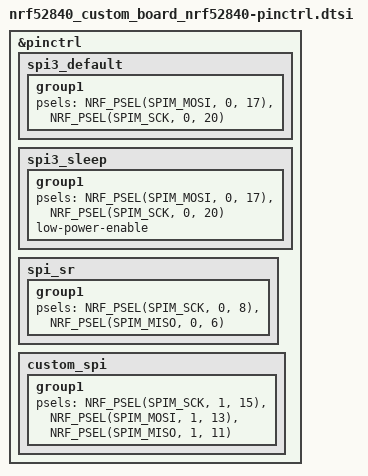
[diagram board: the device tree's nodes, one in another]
/*
 * Copyright (c) 2022 Nordic Semiconductor
 * SPDX-License-Identifier: Apache-2.0
 */

&pinctrl {
	spi3_default: spi3_default {
		group1 {
			psels = <NRF_PSEL(SPIM_MOSI, 0, 17)>,
					<NRF_PSEL(SPIM_SCK, 0, 20)>;
		};
	};

	spi3_sleep: spi3_sleep {
		group1 {
			psels = <NRF_PSEL(SPIM_MOSI, 0, 17)>,
					<NRF_PSEL(SPIM_SCK, 0, 20)>;
			low-power-enable;
		};
	};

	spi_sr: spi_sr{
		group1 {
            psels = <NRF_PSEL(SPIM_SCK, 0, 8)>, // CLK
					<NRF_PSEL(SPIM_MISO, 0, 6)>; // QH (pin 9)
        };
	};

	custom_spi: custom_spi {
                group1 {
                        psels = <NRF_PSEL(SPIM_SCK, 1, 15)>,
                                <NRF_PSEL(SPIM_MOSI, 1, 13)>,
                                <NRF_PSEL(SPIM_MISO, 1, 11)>;
                };
        };
};
